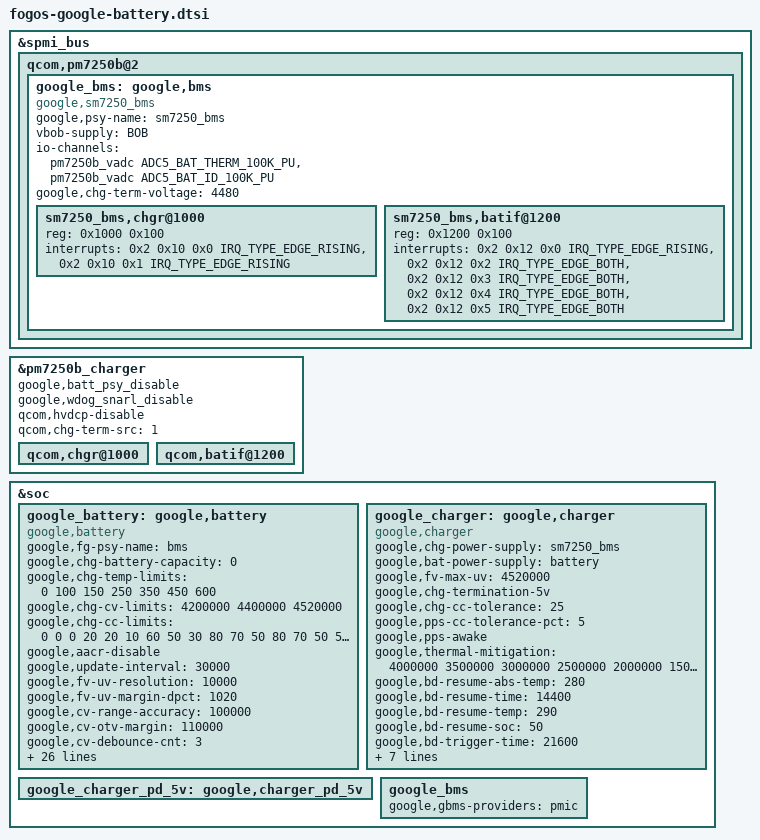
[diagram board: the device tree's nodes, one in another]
// SPDX-License-Identifier: GPL-2.0
/* Copyright (c) 2024, Google LLC. All rights reserved.
 *
 * Google BMS overlay for Moto G34 (fogos) — SM6375 / PM7250B
 */

#include <dt-bindings/interrupt-controller/irq.h>

&spmi_bus {
	qcom,pm7250b@2 {
		google_bms: google,bms {
			compatible = "google,sm7250_bms";
			google,psy-name = "sm7250_bms";
			vbob-supply = <&BOB>;

			io-channels = <&pm7250b_vadc ADC5_BAT_THERM_100K_PU>,
				       <&pm7250b_vadc ADC5_BAT_ID_100K_PU>;
			io-channel-names = "batt-therm", "batt-id";

			google,chg-term-voltage = <4480>;

			sm7250_bms,chgr@1000 {
				reg = <0x1000 0x100>;
				interrupts =
					<0x2 0x10 0x0 IRQ_TYPE_EDGE_RISING>,
					<0x2 0x10 0x1 IRQ_TYPE_EDGE_RISING>;
				interrupt-names =
					"chgr-error",
					"chg-state-change";
			};

			sm7250_bms,batif@1200 {
				reg = <0x1200 0x100>;
				interrupts =
					<0x2 0x12 0x0 IRQ_TYPE_EDGE_RISING>,
					<0x2 0x12 0x2 IRQ_TYPE_EDGE_BOTH>,
					<0x2 0x12 0x3 IRQ_TYPE_EDGE_BOTH>,
					<0x2 0x12 0x4 IRQ_TYPE_EDGE_BOTH>,
					<0x2 0x12 0x5 IRQ_TYPE_EDGE_BOTH>;
				interrupt-names = "bat-temp",
						  "bat-ov",
						  "bat-low",
						  "bat-therm-or-id-missing",
						  "bat-terminal-missing";
			};
		};
	};
};

&pm7250b_charger {
	google,batt_psy_disable;
	google,wdog_snarl_disable;
	qcom,hvdcp-disable;
	qcom,chg-term-src = <1>;

	qcom,chgr@1000 {
		/delete-property/ interrupts;
		/delete-property/ interrupt-names;
	};

	qcom,batif@1200 {
		/delete-property/ interrupts;
		/delete-property/ interrupt-names;
	};
};

&soc {
	google_battery: google,battery {
		compatible = "google,battery";
		google,fg-psy-name = "bms";

		/* chg-battery-capacity = <0> -> read FULL_DESIGN from FG */
		google,chg-battery-capacity = <0>;

		/*
		 * Charge table for fogos (5000 mAh)
		 * Temp tiers (deci-°C): 0 / 10 / 15 / 25 / 35 / 45 / 60
		 * Voltage tiers (µV):   4.20V / 4.40V / 4.52V
		 * CC limits in centirate of capacity (e.g. 80 = 0.8C = 4000mA)
		 */
		google,chg-temp-limits = <0 100 150 250 350 450 600>;
		google,chg-cv-limits = <4200000 4400000 4520000>;
		google,chg-cc-limits = <
			/* <10°C  */ 0    0    0
			/* 10-15  */ 20   20   10
			/* 15-25  */ 60   50   30
			/* 25-35  */ 80   70   50
			/* 35-45  */ 80   70   50
			/* 45-60  */ 50   30    0
		>;

		google,aacr-disable;

		/* battery poll rate */
		google,update-interval = <30000>;
		/* IRDrop Compensation */
		google,fv-uv-resolution = <10000>;
		google,fv-uv-margin-dpct = <1020>;
		/* tier switch */
		google,cv-range-accuracy = <100000>;
		google,cv-otv-margin = <110000>;
		google,cv-debounce-cnt = <3>;
		google,cv-tier-ov-cnt = <1>;
		google,cv-tier-switch-cnt = <3>;
		/* resistance estimation */
		google,res-temp-hi = <390>;
		google,res-temp-lo = <350>;
		google,res-soc-thresh = <75>;
		google,res-filt-length = <10>;
		/* enable cycle counts */
		google,cycle-counts;

		#thermal-sensor-cells = <0>;

		/* soc smoothing */
		google,rl_delta-max-soc = <1>;
		google,rl_delta-max-time = <15>;
		google,rl_ft-low-limit = <7>;
		google,rl_ft-delta-limit = <15>;
		google,rl_st-delta-limit = <7>;
		google,rl_st-max-count = <3>;
		google,rl_no-zero;
		google,rl_soc-limits = <20 30 40 50 60 70 90 100>;
		google,rl_soc-rates =  <25 26 27 28 29 28 27 22>;

		/* rest charging */
		google,chg-rest-rate = <15>;
		google,chg-rest-soc = <80>;

		google,ssoc-delta = <2>;

		/* TRICKLE-DEFEND */
		google,bd-trickle-recharge-soc = <80>;
		google,bd-trickle-enable;

		/* TTF tables for 5000 mAh */
		google,ttf-adapter = <3000>;
		google,ttf-soc-table = <49 57 72 80 86 90 93 100>;
		google,ttf-elap-table = <45 55 70 90 110 140 190 230>;
		google,ttf-tier-table = <0 62 85>;
	};

	google_charger: google,charger {
		compatible = "google,charger";
		#cooling-cells = <2>;
		google,chg-power-supply = "sm7250_bms";
		google,bat-power-supply = "battery";

		google,fv-max-uv = <4520000>;
		google,chg-termination-5v;

		google,chg-cc-tolerance = <25>;
		google,pps-cc-tolerance-pct = <5>;
		google,pps-awake;

		google,thermal-mitigation = <4000000 3500000 3000000
					     2500000 2000000 1500000
					     1200000 900000 600000>;

		/* TEMP-DEFEND (Battery Defender) */
		google,bd-resume-abs-temp = <280>;
		google,bd-resume-time = <14400>;   /* 4 hours */
		google,bd-resume-temp = <290>;
		google,bd-resume-soc = <50>;
		google,bd-trigger-time = <21600>;  /* 6 hours */
		google,bd-trigger-temp = <350>;
		google,bd-trigger-voltage = <4400000>;
		google,bd-recharge-voltage = <4380000>;
		google,bd-drainto-soc = <80>;
		google,bd-recharge-soc = <79>;
		/* Enable TEMP-DEFEND in dry-run */
		google,bd-temp-enable;
		google,bd-temp-dry-run;
	};

	google_charger_pd_5v: google,charger_pd_5v {
		#cooling-cells = <2>;
	};

	google_bms {
		google,gbms-providers = "pmic";
	};
};
